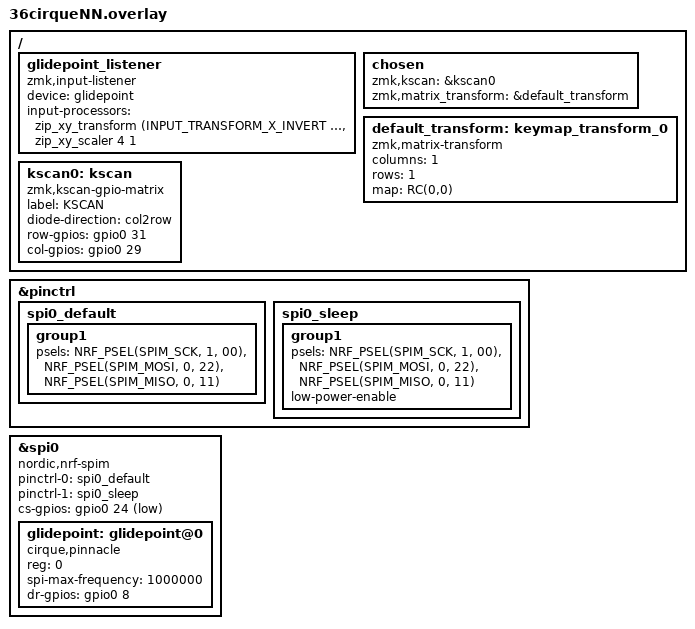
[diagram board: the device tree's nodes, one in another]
// This is default overlay for the Cirque Glidepoint touchpad connected via SPI.

#include <dt-bindings/zmk/matrix_transform.h>
#include <dt-bindings/zmk/input_transform.h>
#include <input/processors.dtsi>

&pinctrl {/* configuration for spi1 device, default state */
    spi0_default: spi0_default {/* node name is arbitrary */
        group1 {
            /* 
                main role: For nice!nano, configure P0.11 as SPI clock, P0.22 as SPI MOSI, P0.08 as SPI MISO 
                           For Xiao NRF, default pins are: P1.13 as SPI Clock, P1.15 as SPI MOSI, P1.14 as SPI MISO
            */
            psels = <NRF_PSEL(SPIM_SCK,  1, 00)>, // D6
                    <NRF_PSEL(SPIM_MOSI, 0, 22)>, // D3
                    <NRF_PSEL(SPIM_MISO, 0, 11)>; // D7
            };
        };
    /* configuration for spi1 device, sleep state */
    spi0_sleep: spi0_sleep {
        group1 {
            /* main role: configure P0.11 as SPI clock, P0.22 as SPI MOSI, P0.08 as SPI MISO */
            psels = <NRF_PSEL(SPIM_SCK,  1, 00)>, // D6
                    <NRF_PSEL(SPIM_MOSI, 0, 22)>, // D3
                    <NRF_PSEL(SPIM_MISO, 0, 11)>; // D7
            low-power-enable;
            };
        };
    };
&spi0 {
    compatible = "nordic,nrf-spim";
    pinctrl-0 = <&spi0_default>;
    pinctrl-1 = <&spi0_sleep>;
    pinctrl-names = "default", "sleep";
};

&spi0 {
    status = "okay";
    cs-gpios = <&gpio0 24 GPIO_ACTIVE_LOW>;
    glidepoint: glidepoint@0 {
        compatible = "cirque,pinnacle";
        reg = <0>;
        spi-max-frequency = <1000000>;
        status = "okay";
        dr-gpios = <&gpio0 8 (GPIO_ACTIVE_HIGH)>; 
    };
};

/ {
    glidepoint_listener {
        compatible = "zmk,input-listener";
        device = <&glidepoint>;
        // input-processors = <&zip_xy_transform (INPUT_TRANSFORM_XY_SWAP)>;
        input-processors = <
            &zip_xy_transform (INPUT_TRANSFORM_X_INVERT | INPUT_TRANSFORM_Y_INVERT | INPUT_TRANSFORM_XY_SWAP)
            &zip_xy_scaler 4 1
        >; 
    };
};
/ {

    chosen {
        zmk,kscan = &kscan0;
        zmk,matrix_transform = &default_transform;
    };
    
    default_transform: keymap_transform_0 {
        compatible = "zmk,matrix-transform";
        columns = <1>;
        rows = <1>;
        map = <RC(0,0)>;
    };
    
    kscan0: kscan {
        compatible = "zmk,kscan-gpio-matrix";
        label = "KSCAN";
        diode-direction = "col2row";
        row-gpios
            = <&gpio0 31 (GPIO_ACTIVE_HIGH | GPIO_PULL_DOWN)>
            ;
        col-gpios
            = <&gpio0 29 GPIO_ACTIVE_HIGH>
            ;
    };
};
/* 
Adapter Back vs Front Pinouts:
1=12
2=11
3=10
4=9
5=8
6=7
7=6
8=5
9=4
10=3
11=2
12=1

Cirque Pinout:
1 SCK to P1.00(D6)
2 MISO to P0.11(D7)
3 SS to P0.24(D5)
4 DR to P0.08 (D0) 
5 MOSI to P0.22(D3)
6 BTN2
7 BTN3
8 BTN1
9 SCL to P0.17(D2)
10 SDA to P0.06(D1)
11 GND to GND
12 VDD to 3.3v 

Without Acceleration (working):
west build -d build/36cirqueNN -p -b nice_nano_v2 -- -DSHIELD=36cirqueNN -DZMK_EXTRA_MODULES="/workspaces/zmk/app/cirque-input-module-main"
west build -d build/36cirqueNN -p -b nice_nano -- -DSHIELD=36cirqueNN -DZMK_EXTRA_MODULES="/workspaces/zmk/app/cirque-input-module-main"

docker cp wizardly_wiles:/workspaces/zmk/app/build/36CirqueNN/zephyr/zmk.uf2 '/Users/song100/Library/Mobile Documents/com~apple~CloudDocs/Keyboard/36firmware/36CirqueNN.uf2'
*/

